# AT32F415xx_v2 register map
Vendor: Keil; Series: AT32F415; File version: 1.0
CPU: CM4 r0p1, little endian, no MPU, FPU, 4 interrupt priority bits
Registers are 32-bit, read-write, reset 0x0 unless marked. A register's access mark holds for its fields unless they carry their own. Offsets are from the block's base; [hi:lo] are bit positions; {n}, {i} and the like mark numbered series.

## USART1 — Universal synchronous asynchronous receiver transmitter
Base 0x40013800
Same registers: USART2 0x40004400, USART3 0x40004800, UART4 0x40004C00, UART5 0x40005000
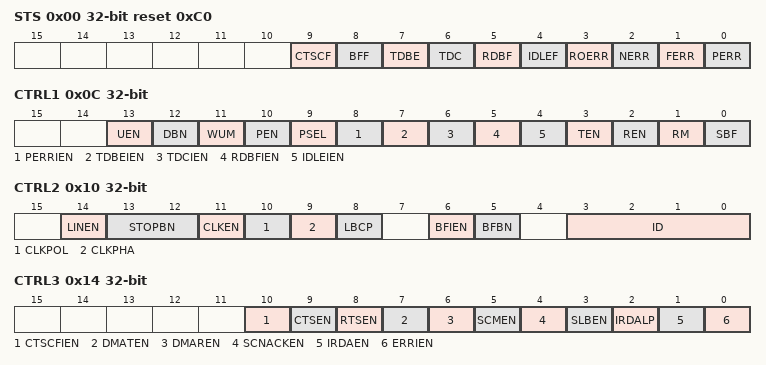
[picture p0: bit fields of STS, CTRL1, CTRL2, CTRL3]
0x00 STS reset 0xC0 — Status register
  [9] CTSCF — CTS change flag
  [8] BFF — Break frame flag
  [7] TDBE ro — Transmit data buffer empty
  [6] TDC — Transmit data complete
  [5] RDBF — Receive data buffer full
  [4] IDLEF ro — IDLE flag
  [3] ROERR ro — Receiver overflow error
  [2] NERR ro — Noise error
  [1] FERR ro — Framing error
  [0] PERR ro — Parity error
0x04 DT — Data register
  [8:0] DT — Data value
0x08 BAUDR — Baud rate register
  [15:0] DIV — Division
0x0C CTRL1 — Control register 1
  [13] UEN — USART enable
  [12] DBN — Data bit num
  [11] WUM — Wake up mode
  [10] PEN — Parity enable
  [9] PSEL — Parity selection
  [8] PERRIEN — PERR interrupt enable
  [7] TDBEIEN — TDBE interrupt enable
  [6] TDCIEN — TDC interrupt enable
  [5] RDBFIEN — RDBF interrupt enable
  [4] IDLEIEN — IDLE interrupt enable
  [3] TEN — Transmitter enable
  [2] REN — Receiver enable
  [1] RM — Receiver mute
  [0] SBF — Send break frame
0x10 CTRL2 — Control register 2
  [14] LINEN — LIN mode enable
  [13:12] STOPBN — STOP bit num
  [11] CLKEN — Clock enable
  [10] CLKPOL — Clock polarity
  [9] CLKPHA — Clock phase
  [8] LBCP — Last bit clock pulse
  [6] BFIEN — Break frame interrupt enable
  [5] BFBN — Break frame bit num
  [3:0] ID — USART identification
0x14 CTRL3 — Control register 3
  [10] CTSCFIEN — CTSCF interrupt enable
  [9] CTSEN — CTS enable
  [8] RTSEN — RTS enable
  [7] DMATEN — DMA transmitter enable
  [6] DMAREN — DMA receiver enable
  [5] SCMEN — Smartcard mode enable
  [4] SCNACKEN — Smartcard NACK enable
  [3] SLBEN — Single line bidirectional half-duplex enable
  [2] IRDALP — IrDA low-power mode
  [1] IRDAEN — IrDA enable
  [0] ERRIEN — Error interrupt enable
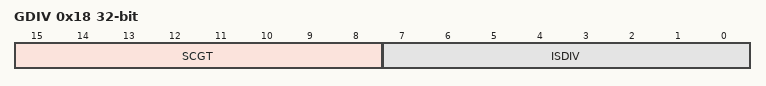
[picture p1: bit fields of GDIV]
0x18 GDIV — Guard time and division register
  [15:8] SCGT — Smart card guard time value
  [7:0] ISDIV — IrDA/smartcard division value

## CMP — Comparator
Base 0x40002400
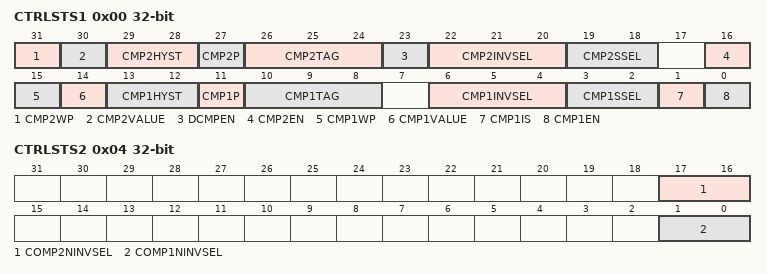
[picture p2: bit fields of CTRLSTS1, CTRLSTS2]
0x00 CTRLSTS1 — CMP control/status register1
  [31] CMP2WP — Comparator2 write protect
  [30] CMP2VALUE ro — Comparator2 output value
  [29:28] CMP2HYST — Comparator2 hysteresis
  [27] CMP2P — Comparator2 polarity
  [26:24] CMP2TAG — Comparator2 output target
  [23] DCMPEN — Double comparator mode enable
  [22:20] CMP2INVSEL — Comparator2 inverting selection
  [19:18] CMP2SSEL — Comparator2 speed selection
  [16] CMP2EN — Comparator2 enable bit
  [15] CMP1WP — Comparator1 write protect
  [14] CMP1VALUE ro — Comparator1 output value
  [13:12] CMP1HYST — Comparator1 hysteresis
  [11] CMP1P — Comparator1 polarity
  [10:8] CMP1TAG — Comparator1 output target
  [6:4] CMP1INVSEL — Comparator1 inverting selection
  [3:2] CMP1SSEL — Comparator1 speed selection
  [1] CMP1IS — Comparator1 input shift
  [0] CMP1EN — Comparator1 enable bit
0x04 CTRLSTS2 — CMP control/status register2
  [17:16] COMP2NINVSEL — Comparator2 non-inverting input selection
  [1:0] COMP1NINVSEL — Comparator1 non-inverting input selection

## DEBUG — Debug support
Base 0xE0042000
0x00 DEBUG_IDCODE ro
  [31:0] PID
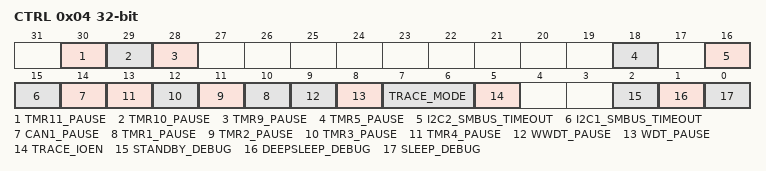
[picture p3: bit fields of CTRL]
0x04 CTRL — MCUDBG_CTRL
  [30] TMR11_PAUSE, [29] TMR10_PAUSE, [28] TMR9_PAUSE, [18] TMR5_PAUSE, [16] I2C2_SMBUS_TIMEOUT, [15] I2C1_SMBUS_TIMEOUT, [14] CAN1_PAUSE, [n+9] TMR{n}_PAUSE (n=1..4), [9] WWDT_PAUSE, [8] WDT_PAUSE, [7:6] TRACE_MODE, [5] TRACE_IOEN, [2] STANDBY_DEBUG, [1] DEEPSLEEP_DEBUG, [0] SLEEP_DEBUG

## CRC — CRC calculation unit
Base 0x40023000
0x00 DT reset 0xFFFFFFFF — Data register
  [31:0] DT — Data Register
0x04 CDT — Common data register
  [7:0] CDT — Common Data
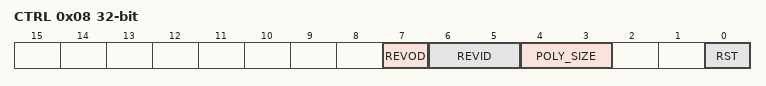
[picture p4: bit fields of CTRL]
0x08 CTRL — Control register
  [7] REVOD — Reverse output data
  [6:5] REVID — Reverse input data
  [4:3] POLY_SIZE — Polynomial size
  [0] RST — Reset bit
0x10 IDT reset 0xFFFFFFFF — Initial data register
  [31:0] IDT — Initial Data
0x14 POLY reset 0x4C11DB7 — Polynomial coefficient register
  [31:0] POLY — polynomial coefficient
